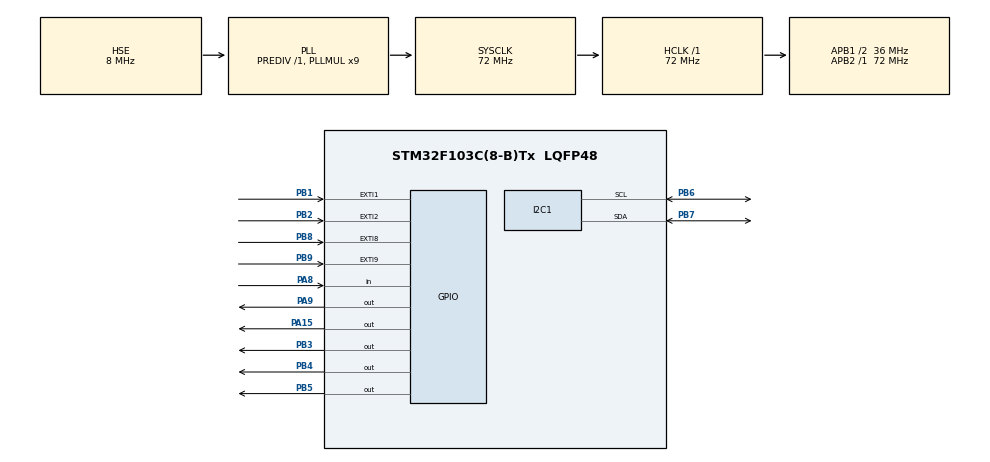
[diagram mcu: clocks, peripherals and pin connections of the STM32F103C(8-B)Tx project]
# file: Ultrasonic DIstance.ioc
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I2C1.I2C_Mode=I2C_Fast
Mcu.Family=STM32F1
Mcu.Name=STM32F103C(8-B)Tx
Mcu.Package=LQFP48
NVIC.EXTI9_5_IRQn=true\:0\:0\:false\:false\:true\:true\:true\:true
NVIC.PriorityGroup=NVIC_PRIORITYGROUP_4
PA13.Mode=Serial_Wire
PA13.Signal=SYS_JTMS-SWDIO
PA14.Mode=Serial_Wire
PA14.Signal=SYS_JTCK-SWCLK
PA15.Signal=GPIO_Output
PA8.Signal=GPIO_Input
PA9.Signal=GPIO_Output
PB1.Signal=GPXTI1
PB2.Signal=GPXTI2
PB3.Signal=GPIO_Output
PB4.Signal=GPIO_Output
PB5.Signal=GPIO_Output
PB6.Mode=I2C
PB6.Signal=I2C1_SCL
PB7.Mode=I2C
PB7.Signal=I2C1_SDA
PB8.Signal=GPXTI8
PB9.Signal=GPXTI9
PD0-OSC_IN.Mode=HSE-External-Oscillator
PD0-OSC_IN.Signal=RCC_OSC_IN
PD1-OSC_OUT.Mode=HSE-External-Oscillator
PD1-OSC_OUT.Signal=RCC_OSC_OUT
ProjectManager.HeapSize=0x200
ProjectManager.StackSize=0x400
ProjectManager.TargetToolchain=MDK-ARM V5.32
RCC.AHBFreq_Value=72000000
RCC.APB1CLKDivider=RCC_HCLK_DIV2
RCC.APB1Freq_Value=36000000
RCC.APB1TimFreq_Value=72000000
RCC.APB2Freq_Value=72000000
RCC.APB2TimFreq_Value=72000000
RCC.HCLKFreq_Value=72000000
RCC.PLLMUL=RCC_PLL_MUL9
RCC.PLLSourceVirtual=RCC_PLLSOURCE_HSE
RCC.SYSCLKFreq_VALUE=72000000
RCC.SYSCLKSource=RCC_SYSCLKSOURCE_PLLCLK
RCC.USBFreq_Value=72000000
TIM1.Prescaler=71
VP_TIM1_VS_ClockSourceINT.Mode=Internal
board=custom

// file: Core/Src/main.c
/* USER CODE BEGIN Header */
/**
  ******************************************************************************
  * @file           : main.c
  * @brief          : Main program body
  ******************************************************************************
  * @attention
  *
  * Copyright (c) 2025 STMicroelectronics.
  * All rights reserved.
  *
  * This software is licensed under terms which can be found in the LICENSE file
  * in the root directory of this software component.
  *
  ******************************************************************************
  */
/* USER CODE END Header */
#include "main.h"

/* USER CODE BEGIN Includes */
#include "fonts.h"
#include "ssd1306.h"
#include "stdio.h"
/* USER CODE END Includes */

/* USER CODE BEGIN PD */
#define DIST_LIMIT 10  // Default distance limit in cm
/* USER CODE END PD */

I2C_HandleTypeDef hi2c1;
TIM_HandleTypeDef htim1;

/* USER CODE BEGIN PV */
#define TRIG_PIN GPIO_PIN_9
#define TRIG_PORT GPIOA
#define ECHO_PIN GPIO_PIN_8
#define ECHO_PORT GPIOA

uint32_t pMillis;
uint32_t Value1 = 0;
uint32_t Value2 = 0;
uint16_t Distance  = 0;  // cm
char strCopy[20];
char unitLine[20];

uint8_t unitMode = 0; // 0 = cm, 1 = feet, 2 = inches

// 4x4 keypad layout
char keypad[4][4] = {
  {'1','2','3','A'},
  {'4','5','6','B'},
  {'7','8','9','C'},
  {'*','0','#','D'}
};
/* USER CODE END PV */

void SystemClock_Config(void);
static void MX_GPIO_Init(void);
static void MX_I2C1_Init(void);
static void MX_TIM1_Init(void);
/* USER CODE BEGIN PFP */
char Keypad_GetKey(void);
/* USER CODE END PFP */

/* USER CODE BEGIN 0 */
char Keypad_GetKey(void) {
    for (int col = 0; col < 4; col++) {
        // Set all cols high
        HAL_GPIO_WritePin(GPIOB, GPIO_PIN_3|GPIO_PIN_4|GPIO_PIN_5, GPIO_PIN_SET);
        HAL_GPIO_WritePin(GPIOA, GPIO_PIN_15, GPIO_PIN_SET);

        // Drive one column low
        switch(col) {
            case 0: HAL_GPIO_WritePin(GPIOB, GPIO_PIN_3, GPIO_PIN_RESET); break;
            case 1: HAL_GPIO_WritePin(GPIOB, GPIO_PIN_4, GPIO_PIN_RESET); break;
            case 2: HAL_GPIO_WritePin(GPIOB, GPIO_PIN_5, GPIO_PIN_RESET); break;
            case 3: HAL_GPIO_WritePin(GPIOA, GPIO_PIN_15, GPIO_PIN_RESET); break;
        }

        HAL_Delay(1); // small delay

        // Read rows
        if (HAL_GPIO_ReadPin(GPIOB, GPIO_PIN_0) == GPIO_PIN_RESET) return keypad[0][col];
        if (HAL_GPIO_ReadPin(GPIOB, GPIO_PIN_1) == GPIO_PIN_RESET) return keypad[1][col];
        if (HAL_GPIO_ReadPin(GPIOB, GPIO_PIN_8) == GPIO_PIN_RESET) return keypad[2][col];
        if (HAL_GPIO_ReadPin(GPIOB, GPIO_PIN_9) == GPIO_PIN_RESET) return keypad[3][col];
    }
    return 0; // No key pressed
}
/* USER CODE END 0 */

int main(void)
{
  /* MCU Configuration--------------------------------------------------------*/
  HAL_Init();
  SystemClock_Config();

  MX_GPIO_Init();
  MX_I2C1_Init();
  MX_TIM1_Init();

  /* USER CODE BEGIN 2 */
  HAL_TIM_Base_Start(&htim1);
  HAL_GPIO_WritePin(TRIG_PORT, TRIG_PIN, GPIO_PIN_RESET);  // pull the TRIG pin low
  SSD1306_Init();
  /* USER CODE END 2 */

  /* Infinite loop */
  while (1)
  {
    // --- Ultrasonic measurement ---
    HAL_GPIO_WritePin(TRIG_PORT, TRIG_PIN, GPIO_PIN_SET);
    __HAL_TIM_SET_COUNTER(&htim1, 0);
    while (__HAL_TIM_GET_COUNTER(&htim1) < 10);
    HAL_GPIO_WritePin(TRIG_PORT, TRIG_PIN, GPIO_PIN_RESET);

    pMillis = HAL_GetTick();
    while (!(HAL_GPIO_ReadPin(ECHO_PORT, ECHO_PIN)) && (HAL_GetTick() - pMillis < 50));
    Value1 = __HAL_TIM_GET_COUNTER(&htim1);

    pMillis = HAL_GetTick();
    while ((HAL_GPIO_ReadPin(ECHO_PORT, ECHO_PIN)) && (HAL_GetTick() - pMillis < 50));
    Value2 = __HAL_TIM_GET_COUNTER(&htim1);

    Distance = (Value2 - Value1) * 0.034 / 2;  // cm

    // --- Check keypad ---
    char key = Keypad_GetKey();
    if (key == 'A') {
        unitMode++;
        if (unitMode > 2) unitMode = 0; // cycle through 0,1,2
        HAL_Delay(150); // debounce
    }

    // --- OLED Display ---
    SSD1306_Clear();

    if (unitMode == 0) {
        sprintf(strCopy, "Distnce: %d cm", Distance);
        sprintf(unitLine, "Unit: Centimeter");
    } else if (unitMode == 1) {
        float feet = Distance / 30.48;
        sprintf(strCopy, "Distnce: %.2f ft", feet);
        sprintf(unitLine, "Unit: Feet");
    } else {
        float inches = Distance / 2.54;
        sprintf(strCopy, "Distnce: %.1f in", inches);
        sprintf(unitLine, "Unit: Inch");
    }

    SSD1306_GotoXY(10, 10);
    SSD1306_Puts(strCopy, &Font_7x10, 1);
    SSD1306_GotoXY(10, 25);
    SSD1306_Puts(unitLine, &Font_7x10, 1);
    SSD1306_UpdateScreen();

    HAL_Delay(200);
  }
}

void SystemClock_Config(void)
{
  RCC_OscInitTypeDef RCC_OscInitStruct = {0};
  RCC_ClkInitTypeDef RCC_ClkInitStruct = {0};

  RCC_OscInitStruct.OscillatorType = RCC_OSCILLATORTYPE_HSE;
  RCC_OscInitStruct.HSEState = RCC_HSE_ON;
  RCC_OscInitStruct.HSEPredivValue = RCC_HSE_PREDIV_DIV1;
  RCC_OscInitStruct.HSIState = RCC_HSI_ON;
  RCC_OscInitStruct.PLL.PLLState = RCC_PLL_ON;
  RCC_OscInitStruct.PLL.PLLSource = RCC_PLLSOURCE_HSE;
  RCC_OscInitStruct.PLL.PLLMUL = RCC_PLL_MUL9;
  if (HAL_RCC_OscConfig(&RCC_OscInitStruct) != HAL_OK) {
    Error_Handler();
  }

  RCC_ClkInitStruct.ClockType = RCC_CLOCKTYPE_HCLK|RCC_CLOCKTYPE_SYSCLK
                              |RCC_CLOCKTYPE_PCLK1|RCC_CLOCKTYPE_PCLK2;
  RCC_ClkInitStruct.SYSCLKSource = RCC_SYSCLKSOURCE_PLLCLK;
  RCC_ClkInitStruct.AHBCLKDivider = RCC_SYSCLK_DIV1;
  RCC_ClkInitStruct.APB1CLKDivider = RCC_HCLK_DIV2;
  RCC_ClkInitStruct.APB2CLKDivider = RCC_HCLK_DIV1;

  if (HAL_RCC_ClockConfig(&RCC_ClkInitStruct, FLASH_LATENCY_2) != HAL_OK) {
    Error_Handler();
  }
}

static void MX_I2C1_Init(void)
{
  hi2c1.Instance = I2C1;
  hi2c1.Init.ClockSpeed = 400000;
  hi2c1.Init.DutyCycle = I2C_DUTYCYCLE_2;
  hi2c1.Init.OwnAddress1 = 0;
  hi2c1.Init.AddressingMode = I2C_ADDRESSINGMODE_7BIT;
  hi2c1.Init.DualAddressMode = I2C_DUALADDRESS_DISABLE;
  hi2c1.Init.OwnAddress2 = 0;
  hi2c1.Init.GeneralCallMode = I2C_GENERALCALL_DISABLE;
  hi2c1.Init.NoStretchMode = I2C_NOSTRETCH_DISABLE;
  if (HAL_I2C_Init(&hi2c1) != HAL_OK) {
    Error_Handler();
  }
}

static void MX_TIM1_Init(void)
{
  TIM_ClockConfigTypeDef sClockSourceConfig = {0};
  TIM_MasterConfigTypeDef sMasterConfig = {0};

  htim1.Instance = TIM1;
  htim1.Init.Prescaler = 71;
  htim1.Init.CounterMode = TIM_COUNTERMODE_UP;
  htim1.Init.Period = 65535;
  htim1.Init.ClockDivision = TIM_CLOCKDIVISION_DIV1;
  htim1.Init.RepetitionCounter = 0;
  htim1.Init.AutoReloadPreload = TIM_AUTORELOAD_PRELOAD_DISABLE;
  if (HAL_TIM_Base_Init(&htim1) != HAL_OK) {
    Error_Handler();
  }
  sClockSourceConfig.ClockSource = TIM_CLOCKSOURCE_INTERNAL;
  if (HAL_TIM_ConfigClockSource(&htim1, &sClockSourceConfig) != HAL_OK) {
    Error_Handler();
  }
  sMasterConfig.MasterOutputTrigger = TIM_TRGO_RESET;
  sMasterConfig.MasterSlaveMode = TIM_MASTERSLAVEMODE_DISABLE;
  if (HAL_TIMEx_MasterConfigSynchronization(&htim1, &sMasterConfig) != HAL_OK) {
    Error_Handler();
  }
}

static void MX_GPIO_Init(void)
{
  GPIO_InitTypeDef GPIO_InitStruct = {0};

  __HAL_RCC_GPIOD_CLK_ENABLE();
  __HAL_RCC_GPIOB_CLK_ENABLE();
  __HAL_RCC_GPIOA_CLK_ENABLE();

  // TRIG + other outputs
  HAL_GPIO_WritePin(GPIOA, GPIO_PIN_9|GPIO_PIN_15, GPIO_PIN_RESET);
  HAL_GPIO_WritePin(GPIOB, GPIO_PIN_3|GPIO_PIN_4|GPIO_PIN_5, GPIO_PIN_RESET);

  // Keypad rows as inputs
  GPIO_InitStruct.Pin = GPIO_PIN_0|GPIO_PIN_1|GPIO_PIN_8|GPIO_PIN_9;
  GPIO_InitStruct.Mode = GPIO_MODE_INPUT;
  GPIO_InitStruct.Pull = GPIO_PULLUP;
  HAL_GPIO_Init(GPIOB, &GPIO_InitStruct);

  // ECHO pin
  GPIO_InitStruct.Pin = GPIO_PIN_8;
  GPIO_InitStruct.Mode = GPIO_MODE_INPUT;
  GPIO_InitStruct.Pull = GPIO_NOPULL;
  HAL_GPIO_Init(GPIOA, &GPIO_InitStruct);

  // TRIG + keypad cols as outputs
  GPIO_InitStruct.Pin = GPIO_PIN_9|GPIO_PIN_15;
  GPIO_InitStruct.Mode = GPIO_MODE_OUTPUT_PP;
  GPIO_InitStruct.Pull = GPIO_NOPULL;
  GPIO_InitStruct.Speed = GPIO_SPEED_FREQ_LOW;
  HAL_GPIO_Init(GPIOA, &GPIO_InitStruct);

  GPIO_InitStruct.Pin = GPIO_PIN_3|GPIO_PIN_4|GPIO_PIN_5;
  GPIO_InitStruct.Mode = GPIO_MODE_OUTPUT_PP;
  GPIO_InitStruct.Pull = GPIO_NOPULL;
  GPIO_InitStruct.Speed = GPIO_SPEED_FREQ_LOW;
  HAL_GPIO_Init(GPIOB, &GPIO_InitStruct);
}

void Error_Handler(void)
{
  __disable_irq();
  while (1) {}
}
